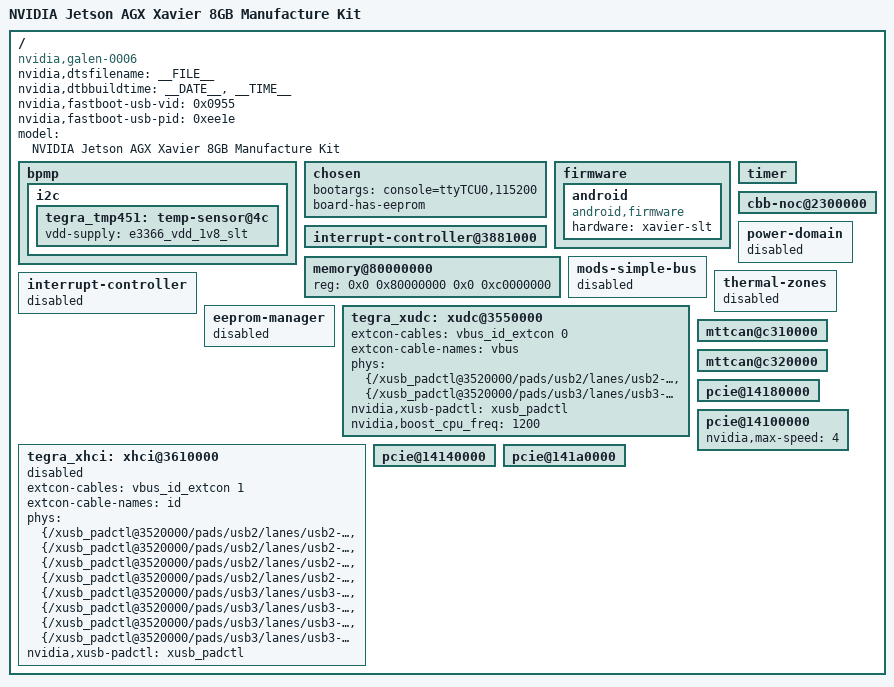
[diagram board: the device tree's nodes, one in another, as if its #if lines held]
/*
 * Copyright (c) 2017-2020, NVIDIA CORPORATION.  All rights reserved.
 *
 * This program is free software; you can redistribute it and/or modify it
 * under the terms and conditions of the GNU General Public License,
 * version 2, as published by the Free Software Foundation.
 *
 * This program is distributed in the hope it will be useful, but WITHOUT
 * ANY WARRANTY; without even the implied warranty of MERCHANTABILITY or
 * FITNESS FOR A PARTICULAR PURPOSE.  See the GNU General Public License for
 * more details.
 *
 * You should have received a copy of the GNU General Public License
 * along with this program.  If not, see <http://www.gnu.org/licenses/>.
 */

/*
 * Top level DTS file for CVM:P2888-0006 and CVB:E3366-1199
 */

#include "common/tegra194-p2888-0000-a00.dtsi"
#include <t19x-common-platforms/tegra194-platforms-eqos.dtsi>
#include "common/tegra194-e3366-1199-a00.dtsi"
#include "common/tegra194-power-tree-p2888-0001-e3366-1199.dtsi"
#include <t19x-common-platforms/tegra194-thermal.dtsi>
#include "common/tegra194-audio-p2822-0000.dtsi"
#include "common/tegra194-plugin-manager-e3366-1199.dtsi"
#include "dt-bindings/soc/gv11b-fuse.h"

/ {
	nvidia,dtsfilename = __FILE__;
	nvidia,dtbbuildtime = __DATE__, __TIME__;
	nvidia,fastboot-usb-vid = <0x0955>;
	nvidia,fastboot-usb-pid = <0xee1e>;

	model = "NVIDIA Jetson AGX Xavier 8GB Manufacture Kit";

	compatible = "nvidia,galen-0006", "nvidia,tegra194";

#if TEGRA_BPMP_FW_DT_VERSION >= DT_VERSION_2
	bpmp { i2c {
#else
	bpmp_i2c {
#endif
		tegra_tmp451: temp-sensor@4c {
			vdd-supply = <&e3366_vdd_1v8_slt>;
		};
#if TEGRA_BPMP_FW_DT_VERSION >= DT_VERSION_2
	}; };
#else
	};
#endif

	chosen {
		bootargs ="console=ttyTCU0,115200";
		board-has-eeprom;
	};

	firmware {
		android {
			compatible = "android,firmware";
			hardware = "xavier-slt";
		};
	};

	timer {
		status = "okay";
	};

	interrupt-controller@3881000 {
		status = "okay";
	};

	memory@80000000 {
		device_type = "memory";
		reg = <0x0 0x80000000 0x0 0xc0000000>;
	};

	cbb-noc@2300000 {
		status = "okay";
	};

	power-domain {
		status = "disabled";
	};

	mods-simple-bus {
		status = "disabled";
	};

	thermal-zones {
		status = "disabled";
	};

	interrupt-controller {
		status = "disabled";
	};

	eeprom-manager {
		status = "disabled";
	};

	tegra_xudc: xudc@3550000 {
#if TEGRA_XUSB_DT_VERSION < DT_VERSION_3
		extcon-cables = <&vbus_id_extcon 0>;
		extcon-cable-names = "vbus";
		#extcon-cells = <1>;
#endif
		phys = <&{/xusb_padctl@3520000/pads/usb2/lanes/usb2-0}>,
			<&{/xusb_padctl@3520000/pads/usb3/lanes/usb3-2}>;
#if TEGRA_XUSB_DT_VERSION >= DT_VERSION_3
		phy-names = "usb2-0", "usb3-2";
#else
		phy-names = "usb2", "usb3";
#endif
		nvidia,xusb-padctl = <&xusb_padctl>;
		nvidia,boost_cpu_freq = <1200>;
		status = "okay";
	};

	tegra_xhci: xhci@3610000 {
#if TEGRA_XUSB_DT_VERSION < DT_VERSION_3
		extcon-cables = <&vbus_id_extcon 1>;
		extcon-cable-names = "id";
		#extcon-cells = <1>;
#endif
		phys = <&{/xusb_padctl@3520000/pads/usb2/lanes/usb2-0}>,
			<&{/xusb_padctl@3520000/pads/usb2/lanes/usb2-1}>,
			<&{/xusb_padctl@3520000/pads/usb2/lanes/usb2-2}>,
			<&{/xusb_padctl@3520000/pads/usb2/lanes/usb2-3}>,
			<&{/xusb_padctl@3520000/pads/usb3/lanes/usb3-0}>,
			<&{/xusb_padctl@3520000/pads/usb3/lanes/usb3-1}>,
			<&{/xusb_padctl@3520000/pads/usb3/lanes/usb3-2}>,
			<&{/xusb_padctl@3520000/pads/usb3/lanes/usb3-3}>;
		phy-names = "usb2-0", "usb2-1", "usb2-2", "usb2-3",
				"usb3-0", "usb3-1", "usb3-2", "usb-3";
		nvidia,xusb-padctl = <&xusb_padctl>;
		status = "disabled";
	};

	mttcan@c310000 {
		status = "okay";
	};

	mttcan@c320000 {
		status = "okay";
	};

	pcie@14180000 {
		/delete-property/ nvidia,enable-power-down;
	};

	pcie@14100000 {
		nvidia,max-speed = <4>;
		/delete-property/ nvidia,enable-power-down;
	};

	pcie@14140000 {
		/delete-property/ nvidia,enable-power-down;
	};

	pcie@141a0000 {
		/delete-property/ nvidia,enable-power-down;
		/delete-property/ nvidia,plat-gpios;
	};
};
